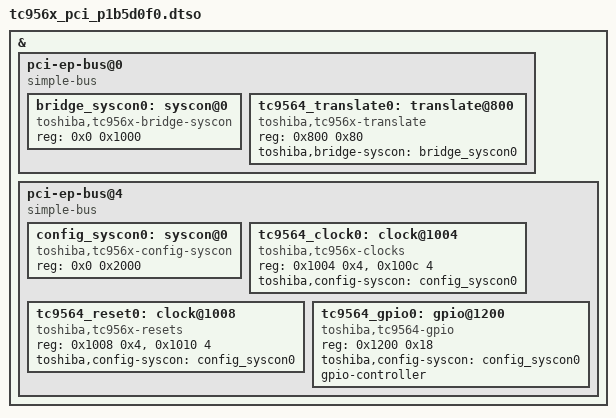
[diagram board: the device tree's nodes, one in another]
// SPDX-License-Identifier: GPL-2.0

/*
 * Devicetree overlay for the TC9564 SoC.  This overlay defines the PCI
 * endpoint bus provided by function 0 of the embedded PCIe endpoint.
 */

/dts-v1/;
/plugin/;

/ {
	fragment@0 {
		target-path = "";

		__overlay__ {
			#address-cells = <3>;
			#size-cells = <2>;

			pci-ep-bus@0 {
				compatible = "simple-bus";
				#address-cells = <1>;
				#size-cells = <1>;
				/* Map 0x0-0x3fff to BAR 0 */
				// ranges = <0x0  0x0 0x0 0x0  0x4000>;
				// ranges = <0x0  0x02000010 0x0 0x0  0x4000>;
				ranges = <0x0  0x02000000 0x0 0x41800000  0x4000>;

				bridge_syscon0: syscon@0 {
					compatible = "toshiba,tc956x-bridge-syscon", "syscon";
					reg = <0x0 0x1000>;
				};

				tc9564_translate0: translate@800 {
					compatible = "toshiba,tc956x-translate";
					reg = <0x800 0x80>;
					toshiba,bridge-syscon = <&bridge_syscon0>;
				};
			};

			pci-ep-bus@4 {
				compatible = "simple-bus";
				#address-cells = <1>;
				#size-cells = <1>;
				/* Map 0x0-0x1fffff to BAR 4 */
				// ranges = <0x0  0x4 0x0 0x0  0x200000>;
				// ranges = <0x0  0x0200001c 0x0 0x0  0x200000>;
				ranges = <0x0  0x02000000 0x0 0x40400000  0x200000>;

				config_syscon0: syscon@0 {
					compatible = "toshiba,tc956x-config-syscon", "syscon";
					reg = <0x0 0x2000>;
				};

				tc9564_clock0: clock@1004 {
					compatible = "toshiba,tc956x-clocks";
					reg = <0x1004 0x4>, <0x100c 4>;
					toshiba,config-syscon = <&config_syscon0>;
					#clock-cells = <1>;
				};

				tc9564_reset0: clock@1008 {
					compatible = "toshiba,tc956x-resets";
					reg = <0x1008 0x4>, <0x1010 4>;
					toshiba,config-syscon = <&config_syscon0>;
					#reset-cells = <1>;
				};

				tc9564_gpio0: gpio@1200 {
					compatible = "toshiba,tc9564-gpio";
					reg = <0x1200 0x18>;
					toshiba,config-syscon = <&config_syscon0>;
					gpio-controller;
					#gpio-cells = <2>;
				};
			};
		};
	};
};
